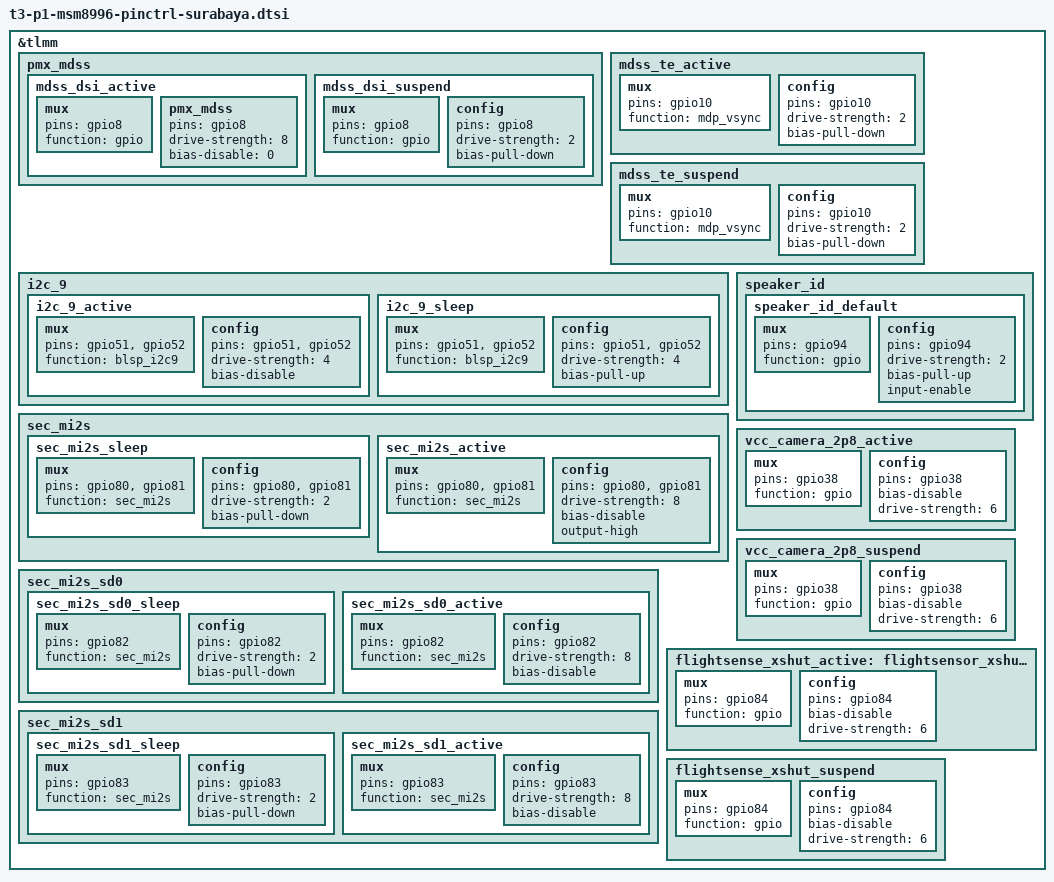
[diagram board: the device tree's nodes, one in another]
/* It inherits from msm8996-pinctrl.dtsi */

&tlmm {
	pmx_mdss: pmx_mdss {
		mdss_dsi_active: mdss_dsi_active {
			mux {
				pins = "gpio8";
				function = "gpio";
			};

			pmx_mdss {
				pins = "gpio8";
				drive-strength = <8>; /* 8 mA */
				bias-disable = <0>; /* no pull */
//				output-low;
			};
		};
		mdss_dsi_suspend: mdss_dsi_suspend {
			mux {
				pins = "gpio8";
				function = "gpio";
			};

			config {
				pins = "gpio8";
				drive-strength = <2>; /* 2 mA */
				bias-pull-down; /* pull down */
//				input-enable;
			};
		};
	};

	mdss_te_active: mdss_te_active {
		mux {
			pins = "gpio10";
			function = "mdp_vsync";
		};
		config {
			pins = "gpio10";
			drive-strength = <2>; /* 8 mA */
			bias-pull-down; /* pull down*/
		};
	};

	mdss_te_suspend: mdss_te_suspend {
		mux {
			pins = "gpio10";
			function = "mdp_vsync";
		};
		config {
			pins = "gpio10";
			drive-strength = <2>; /* 2 mA */
			bias-pull-down; /* pull down */
		};
	};

	i2c_9 {
		i2c_9_active: i2c_9_active {
			mux {
				pins = "gpio51", "gpio52";
				function = "blsp_i2c9";
			};

			config {
				pins = "gpio51", "gpio52";
				drive-strength = <4>;
				bias-disable;
			};
		};

		i2c_9_sleep: i2c_9_sleep {
			mux {
				pins = "gpio51", "gpio52";
				function = "blsp_i2c9";
			};

			config {
				pins = "gpio51", "gpio52";
				drive-strength = <4>;
				bias-pull-up;
			};
		};
	};

	sec_mi2s {
		sec_mi2s_sleep: sec_mi2s_sleep {
			mux {
				pins = "gpio80", "gpio81";
				function = "sec_mi2s";
			};

			config {
				pins = "gpio80", "gpio81";
				drive-strength = <2>;   /* 2 mA */
				bias-pull-down;         /* PULL DOWN */
			};
		};
		sec_mi2s_active: sec_mi2s_active {
			mux {
				pins = "gpio80", "gpio81";
				function = "sec_mi2s";
			};

			config {
				pins = "gpio80", "gpio81";
				drive-strength = <8>;   /* 8 mA */
				bias-disable;           /* NO PULL */
				output-high;
			};
		};
	};

	sec_mi2s_sd0 {
		sec_mi2s_sd0_sleep: sec_mi2s_sd0_sleep {
			mux {
				pins = "gpio82";
				function = "sec_mi2s";
			};

			config {
				pins = "gpio82";
				drive-strength = <2>;   /* 2 mA */
				bias-pull-down;         /* PULL DOWN */
			};
		};
		sec_mi2s_sd0_active: sec_mi2s_sd0_active {
			mux {
				pins = "gpio82";
				function = "sec_mi2s";
			};

			config {
				pins = "gpio82";
				drive-strength = <8>;   /* 8 mA */
				bias-disable;           /* NO PULL */
			};
		};
	};

	sec_mi2s_sd1 {
		sec_mi2s_sd1_sleep: sec_mi2s_sd1_sleep {
			mux {
				pins = "gpio83";
				function = "sec_mi2s";
			};

			config {
				pins = "gpio83";
				drive-strength = <2>;   /* 2 mA */
				bias-pull-down;         /* PULL DOWN */
			};
		};
		sec_mi2s_sd1_active: sec_mi2s_sd1_active {
			mux {
				pins = "gpio83";
				function = "sec_mi2s";
			};

			config {
				pins = "gpio83";
				drive-strength = <8>;   /* 8 mA */
				bias-disable;           /* NO PULL */
			};
		};
	};

	speaker_id {
		speaker_id_default: speaker_id_default {
			mux {
				pins = "gpio94";
				function = "gpio";
			};

			config {
				pins = "gpio94";
				drive-strength = <2>;
				bias-pull-up;
				input-enable;
			};
		};
	};

	vcc_camera_2p8_active: vcc_camera_2p8_active {
		mux {
			pins = "gpio38";
			function = "gpio";
		};

		config {
			pins = "gpio38";
			bias-disable;
                        drive-strength = <6>;  /* 6 MA */
		};

	};

	vcc_camera_2p8_suspend: vcc_camera_2p8_suspend {
		mux {
			pins = "gpio38";
			function = "gpio";
		};

		config {
			pins = "gpio38";
			bias-disable;
                        drive-strength = <6>;  /* 6 MA */
		};

	};

	flightsense_xshut_active: flightsensor_xshut_active {
		mux {
			pins = "gpio84";
			function = "gpio";
		};

		config {
			pins = "gpio84";
			bias-disable;
                        drive-strength = <6>;  /* 6 MA */
		};
	};

	flightsense_xshut_suspend: flightsense_xshut_suspend {
		mux {
			pins = "gpio84";
			function = "gpio";
		};

		config {
			pins = "gpio84";
			bias-disable;           /* pull up */
			drive-strength = <6>;   /* 6 MA */
		};
	};

};
